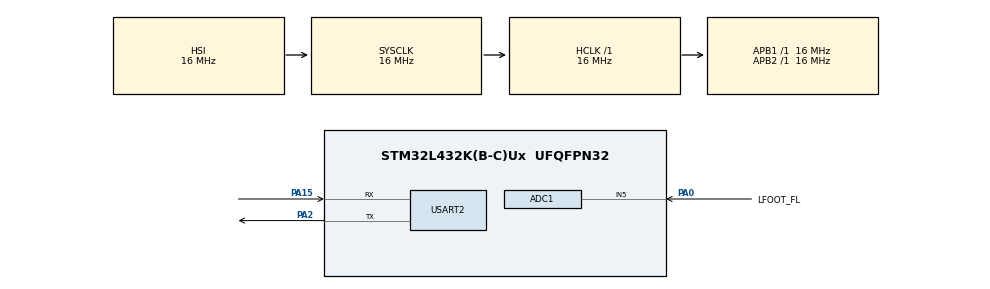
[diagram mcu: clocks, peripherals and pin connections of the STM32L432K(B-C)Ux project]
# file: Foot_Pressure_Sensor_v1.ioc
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ADC1.Channel-0\#ChannelRegularConversion=ADC_CHANNEL_5
ADC1.ClockPrescaler=ADC_CLOCK_ASYNC_DIV8
ADC1.ContinuousConvMode=ENABLE
ADC1.DMAContinuousRequests=ENABLE
ADC1.DataAlign=ADC_DATAALIGN_RIGHT
ADC1.DiscontinuousConvMode=DISABLE
ADC1.EOCSelection=ADC_EOC_SINGLE_CONV
ADC1.EnableAnalogWatchDog1=false
ADC1.EnableAnalogWatchDog2=false
ADC1.EnableAnalogWatchDog3=false
ADC1.EnableInjectedConversion=DISABLE
ADC1.EnableRegularConversion=ENABLE
ADC1.ExternalTrigConv=ADC_SOFTWARE_START
ADC1.ExternalTrigConvEdge=ADC_EXTERNALTRIGCONVEDGE_NONE
ADC1.LowPowerAutoWait=DISABLE
ADC1.NbrOfConversion=1
ADC1.NbrOfConversionFlag=1
ADC1.OffsetNumber-0\#ChannelRegularConversion=ADC_OFFSET_NONE
ADC1.Overrun=ADC_OVR_DATA_PRESERVED
ADC1.OversamplingMode=DISABLE
ADC1.Rank-0\#ChannelRegularConversion=1
ADC1.Resolution=ADC_RESOLUTION_12B
ADC1.SamplingTime-0\#ChannelRegularConversion=ADC_SAMPLETIME_47CYCLES_5
ADC1.ScanConvMode=ADC_SCAN_DISABLE
ADC1.master=1
Dma.ADC1.0.Direction=DMA_PERIPH_TO_MEMORY
Dma.ADC1.0.Instance=DMA1_Channel1
Dma.ADC1.0.MemDataAlignment=DMA_MDATAALIGN_HALFWORD
Dma.ADC1.0.MemInc=DMA_MINC_ENABLE
Dma.ADC1.0.Mode=DMA_CIRCULAR
Dma.ADC1.0.PeriphDataAlignment=DMA_PDATAALIGN_HALFWORD
Dma.ADC1.0.PeriphInc=DMA_PINC_DISABLE
Dma.ADC1.0.Priority=DMA_PRIORITY_LOW
Dma.Request0=ADC1
Mcu.Family=STM32L4
Mcu.Name=STM32L432K(B-C)Ux
Mcu.Package=UFQFPN32
NVIC.ADC1_IRQn=true\:0\:0\:false\:false\:true\:true
NVIC.DMA1_Channel1_IRQn=true\:0\:0\:false\:false\:true\:false
NVIC.PriorityGroup=NVIC_PRIORITYGROUP_4
NVIC.USART2_IRQn=true\:0\:0\:false\:false\:true\:true
PA0.GPIO_Label=LFOOT_FL
PA0.Signal=ADCx_IN5
PA15\ (JTDI).Mode=Asynchronous
PA15\ (JTDI).Signal=USART2_RX
PA2.Mode=Asynchronous
PA2.Signal=USART2_TX
ProjectManager.HeapSize=0x200
ProjectManager.StackSize=0x400
ProjectManager.TargetToolchain=SW4STM32
RCC.ADCFreq_Value=32000000
RCC.AHBFreq_Value=16000000
RCC.APB1Freq_Value=16000000
RCC.APB1TimFreq_Value=16000000
RCC.APB2Freq_Value=16000000
RCC.APB2TimFreq_Value=16000000
RCC.CortexFreq_Value=16000000
RCC.HCLKFreq_Value=16000000
RCC.HSE_VALUE=8000000
RCC.HSI48_VALUE=48000000
RCC.HSI_VALUE=16000000
RCC.LSE_VALUE=32768
RCC.MSI_VALUE=4000000
RCC.PLLN=24
RCC.PLLR=RCC_PLLR_DIV4
RCC.PLLSAI1N=12
RCC.PLLSAI1R=RCC_PLLR_DIV6
RCC.PLLSourceVirtual=RCC_PLLSOURCE_HSI
RCC.SYSCLKFreq_VALUE=16000000
RCC.SYSCLKSource=RCC_SYSCLKSOURCE_HSI
RCC.USBFreq_Value=96000000
RCC.VCOOutputFreq_Value=384000000
SH.ADCx_IN5.0=ADC1_IN5,IN5-Single-Ended
USART2.VirtualMode-Asynchronous=VM_ASYNC
USART2.WordLength=WORDLENGTH_8B
board=Foot_Pressure_Sensor_v1

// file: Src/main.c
/**
  ******************************************************************************
  * @file           : main.c
  * @brief          : Main program body
  ******************************************************************************
  ** This notice applies to any and all portions of this file
  * that are not between comment pairs USER CODE BEGIN and
  * USER CODE END. Other portions of this file, whether
  * inserted by the user or by software development tools
  * are owned by their respective copyright owners.
  *
  * COPYRIGHT(c) 2018 STMicroelectronics
  *
  * Redistribution and use in source and binary forms, with or without modification,
  * are permitted provided that the following conditions are met:
  *   1. Redistributions of source code must retain the above copyright notice,
  *      this list of conditions and the following disclaimer.
  *   2. Redistributions in binary form must reproduce the above copyright notice,
  *      this list of conditions and the following disclaimer in the documentation
  *      and/or other materials provided with the distribution.
  *   3. Neither the name of STMicroelectronics nor the names of its contributors
  *      may be used to endorse or promote products derived from this software
  *      without specific prior written permission.
  *
  * THIS SOFTWARE IS PROVIDED BY THE COPYRIGHT HOLDERS AND CONTRIBUTORS "AS IS"
  * AND ANY EXPRESS OR IMPLIED WARRANTIES, INCLUDING, BUT NOT LIMITED TO, THE
  * IMPLIED WARRANTIES OF MERCHANTABILITY AND FITNESS FOR A PARTICULAR PURPOSE ARE
  * DISCLAIMED. IN NO EVENT SHALL THE COPYRIGHT HOLDER OR CONTRIBUTORS BE LIABLE
  * FOR ANY DIRECT, INDIRECT, INCIDENTAL, SPECIAL, EXEMPLARY, OR CONSEQUENTIAL
  * DAMAGES (INCLUDING, BUT NOT LIMITED TO, PROCUREMENT OF SUBSTITUTE GOODS OR
  * SERVICES; LOSS OF USE, DATA, OR PROFITS; OR BUSINESS INTERRUPTION) HOWEVER
  * CAUSED AND ON ANY THEORY OF LIABILITY, WHETHER IN CONTRACT, STRICT LIABILITY,
  * OR TORT (INCLUDING NEGLIGENCE OR OTHERWISE) ARISING IN ANY WAY OUT OF THE USE
  * OF THIS SOFTWARE, EVEN IF ADVISED OF THE POSSIBILITY OF SUCH DAMAGE.
  *
  ******************************************************************************
  */
#include "main.h"
#include "stm32l4xx_hal.h"
#include "adc.h"
#include "dma.h"
#include "usart.h"
#include "gpio.h"

/* USER CODE BEGIN Includes */
#include "string.h"
/* USER CODE END Includes */

/* USER CODE BEGIN PV */
volatile uint16_t ADC_BUF[64];
volatile uint16_t adc_conv;
/* Private variables ---------------------------------------------------------*/

/* USER CODE END PV */

void SystemClock_Config(void);

/* USER CODE BEGIN PFP */
/* Private function prototypes -----------------------------------------------*/

/* USER CODE END PFP */

/* USER CODE BEGIN 0 */
void HAL_ADC_ConvCpltCallback(ADC_HandleTypeDef* hadc) {
	uint32_t avg=0;
	uint8_t len = sizeof(ADC_BUF)/sizeof(ADC_BUF[0]);
	if (hadc->Instance == ADC1) {
		for(uint8_t i=0 ;i<len;i++){
			avg = avg + ADC_BUF[i];
		}
		avg = avg >> 6;
		adc_conv = (uint16_t) avg;
	}
}
/* USER CODE END 0 */

int main(void)
{

  /* MCU Configuration----------------------------------------------------------*/

  /* Reset of all peripherals, Initializes the Flash interface and the Systick. */
  HAL_Init();

  /* Configure the system clock */
  SystemClock_Config();

  /* Initialize all configured peripherals */
  MX_GPIO_Init();
  MX_DMA_Init();
  MX_ADC1_Init();
  MX_USART2_UART_Init();
  /* USER CODE BEGIN 2 */
  HAL_ADC_Start_DMA(&hadc1, (uint32_t*) ADC_BUF, 64);
  /* USER CODE END 2 */

  /* Infinite loop */
  /* USER CODE BEGIN WHILE */
	while (1) {
		//char mes_buf[50];
		//sprintf(mes_buf, "Val:\t%d\n", adc_conv);
		//HAL_UART_Transmit(&huart2, mes_buf, strlen(mes_buf), 1000);
		HAL_UART_Transmit(&huart2, (uint8_t *)&adc_conv, sizeof(adc_conv), 1000);
		HAL_Delay(10);
  /* USER CODE END WHILE */

	}

}

void SystemClock_Config(void)
{

  RCC_OscInitTypeDef RCC_OscInitStruct;
  RCC_ClkInitTypeDef RCC_ClkInitStruct;
  RCC_PeriphCLKInitTypeDef PeriphClkInit;

    /**Initializes the CPU, AHB and APB busses clocks
    */
  RCC_OscInitStruct.OscillatorType = RCC_OSCILLATORTYPE_HSI;
  RCC_OscInitStruct.HSIState = RCC_HSI_ON;
  RCC_OscInitStruct.HSICalibrationValue = 16;
  RCC_OscInitStruct.PLL.PLLState = RCC_PLL_NONE;
  if (HAL_RCC_OscConfig(&RCC_OscInitStruct) != HAL_OK)
  {
    _Error_Handler(__FILE__, __LINE__);
  }

    /**Initializes the CPU, AHB and APB busses clocks
    */
  RCC_ClkInitStruct.ClockType = RCC_CLOCKTYPE_HCLK|RCC_CLOCKTYPE_SYSCLK
                              |RCC_CLOCKTYPE_PCLK1|RCC_CLOCKTYPE_PCLK2;
  RCC_ClkInitStruct.SYSCLKSource = RCC_SYSCLKSOURCE_HSI;
  RCC_ClkInitStruct.AHBCLKDivider = RCC_SYSCLK_DIV1;
  RCC_ClkInitStruct.APB1CLKDivider = RCC_HCLK_DIV1;
  RCC_ClkInitStruct.APB2CLKDivider = RCC_HCLK_DIV1;

  if (HAL_RCC_ClockConfig(&RCC_ClkInitStruct, FLASH_LATENCY_0) != HAL_OK)
  {
    _Error_Handler(__FILE__, __LINE__);
  }

  PeriphClkInit.PeriphClockSelection = RCC_PERIPHCLK_USART2|RCC_PERIPHCLK_ADC;
  PeriphClkInit.Usart2ClockSelection = RCC_USART2CLKSOURCE_PCLK1;
  PeriphClkInit.AdcClockSelection = RCC_ADCCLKSOURCE_PLLSAI1;
  PeriphClkInit.PLLSAI1.PLLSAI1Source = RCC_PLLSOURCE_HSI;
  PeriphClkInit.PLLSAI1.PLLSAI1M = 1;
  PeriphClkInit.PLLSAI1.PLLSAI1N = 12;
  PeriphClkInit.PLLSAI1.PLLSAI1P = RCC_PLLP_DIV7;
  PeriphClkInit.PLLSAI1.PLLSAI1Q = RCC_PLLQ_DIV2;
  PeriphClkInit.PLLSAI1.PLLSAI1R = RCC_PLLR_DIV6;
  PeriphClkInit.PLLSAI1.PLLSAI1ClockOut = RCC_PLLSAI1_ADC1CLK;
  if (HAL_RCCEx_PeriphCLKConfig(&PeriphClkInit) != HAL_OK)
  {
    _Error_Handler(__FILE__, __LINE__);
  }

    /**Configure the main internal regulator output voltage
    */
  if (HAL_PWREx_ControlVoltageScaling(PWR_REGULATOR_VOLTAGE_SCALE1) != HAL_OK)
  {
    _Error_Handler(__FILE__, __LINE__);
  }

    /**Configure the Systick interrupt time
    */
  HAL_SYSTICK_Config(HAL_RCC_GetHCLKFreq()/1000);

    /**Configure the Systick
    */
  HAL_SYSTICK_CLKSourceConfig(SYSTICK_CLKSOURCE_HCLK);

  /* SysTick_IRQn interrupt configuration */
  HAL_NVIC_SetPriority(SysTick_IRQn, 0, 0);
}

void _Error_Handler(char *file, int line)
{
	while (1) {
	}
}

/************************ (C) COPYRIGHT STMicroelectronics *****END OF FILE****/
